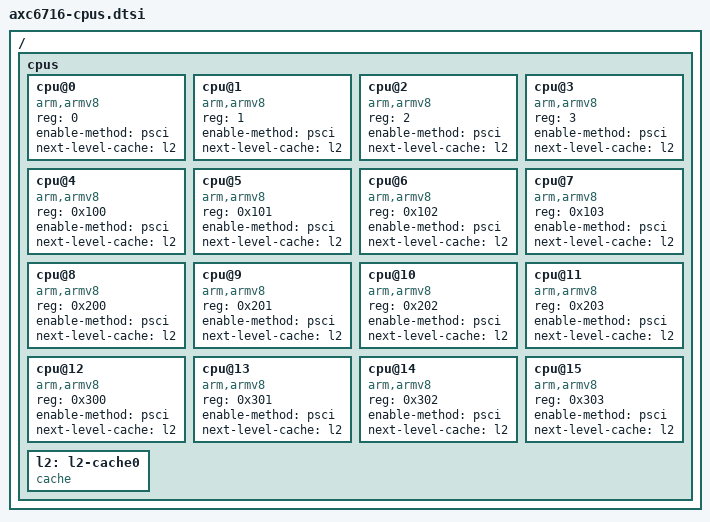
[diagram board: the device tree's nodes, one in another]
// SPDX-License-Identifier: GPL-2.0
// Copyright (C) 2021 INTEL Corporation

/ {
	cpus {
		#address-cells = <1>;
		#size-cells = <0>;

		cpu@0 {
			device_type = "cpu";
			compatible = "arm,armv8";
			reg = <0>;
			enable-method = "psci";
			next-level-cache = <&l2>;
		};

		cpu@1 {
			device_type = "cpu";
			compatible = "arm,armv8";
			reg = <1>;
			enable-method = "psci";
			next-level-cache = <&l2>;
		};

		cpu@2 {
			device_type = "cpu";
			compatible = "arm,armv8";
			reg = <2>;
			enable-method = "psci";
			next-level-cache = <&l2>;
		};

		cpu@3 {
			device_type = "cpu";
			compatible = "arm,armv8";
			reg = <3>;
			enable-method = "psci";
			next-level-cache = <&l2>;
		};

		cpu@4 {
			device_type = "cpu";
			compatible = "arm,armv8";
			reg = <0x100>;
			enable-method = "psci";
			next-level-cache = <&l2>;
		};

		cpu@5 {
			device_type = "cpu";
			compatible = "arm,armv8";
			reg = <0x101>;
			enable-method = "psci";
			next-level-cache = <&l2>;
		};

		cpu@6 {
			device_type = "cpu";
			compatible = "arm,armv8";
			reg = <0x102>;
			enable-method = "psci";
			next-level-cache = <&l2>;
		};

		cpu@7 {
			device_type = "cpu";
			compatible = "arm,armv8";
			reg = <0x103>;
			enable-method = "psci";
			next-level-cache = <&l2>;

		};

		cpu@8 {
			device_type = "cpu";
			compatible = "arm,armv8";
			reg = <0x200>;
			enable-method = "psci";
			next-level-cache = <&l2>;
		};

		cpu@9 {
			device_type = "cpu";
			compatible = "arm,armv8";
			reg = <0x201>;
			enable-method = "psci";
			next-level-cache = <&l2>;
		};

		cpu@10 {
			device_type = "cpu";
			compatible = "arm,armv8";
			reg = <0x202>;
			enable-method = "psci";
			next-level-cache = <&l2>;
		};

		cpu@11 {
			device_type = "cpu";
			compatible = "arm,armv8";
			reg = <0x203>;
			enable-method = "psci";
			next-level-cache = <&l2>;
		};

		cpu@12 {
			device_type = "cpu";
			compatible = "arm,armv8";
			reg = <0x300>;
			enable-method = "psci";
			next-level-cache = <&l2>;
		};

		cpu@13 {
			device_type = "cpu";
			compatible = "arm,armv8";
			reg = <0x301>;
			enable-method = "psci";
			next-level-cache = <&l2>;
		};

		cpu@14 {
			device_type = "cpu";
			compatible = "arm,armv8";
			reg = <0x302>;
			enable-method = "psci";
			next-level-cache = <&l2>;
		};

		cpu@15 {
			device_type = "cpu";
			compatible = "arm,armv8";
			reg = <0x303>;
			enable-method = "psci";
			next-level-cache = <&l2>;

		};

		l2: l2-cache0 {
			compatible = "cache";
		};
	};
};
